# va416xx register map
Vendor: VORAGO TECHNOLOGIES; Series: M4; File version: 1.3
CPU: CM4 r0p1, little endian, no MPU, FPU, 4 interrupt priority bits
Registers are 32-bit, read-write, reset 0x0 unless marked. A register's access mark holds for its fields unless they carry their own. Offsets are from the block's base; [hi:lo] are bit positions; {n}, {i} and the like mark numbered series; 'fields as' and 'values as' point back to an identical list.

## SYSCONFIG — System Configuration Peripheral
Base 0x40010000
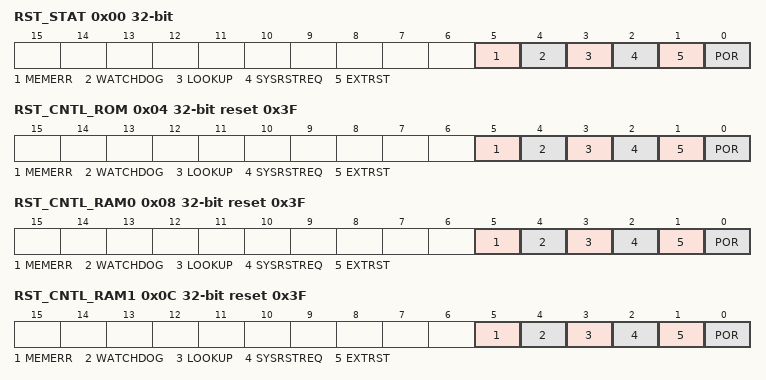
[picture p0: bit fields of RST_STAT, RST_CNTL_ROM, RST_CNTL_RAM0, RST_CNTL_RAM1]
0x00 RST_STAT — System Reset Status
  [5] MEMERR ro — Memory Error Reset Status
  [4] WATCHDOG — WATCHDOG Reset Status
  [3] LOOKUP — LOOKUP Reset Status
  [2] SYSRSTREQ — SYSRESETREQ Reset Status
  [1] EXTRST — External Reset Status
  [0] POR — Power On Reset Status
0x04 RST_CNTL_ROM reset 0x3F — ROM Reset Control
  fields as RST_STAT
0x08 RST_CNTL_RAM0 reset 0x3F — RAM Reset Control
  fields as RST_STAT
0x0C RST_CNTL_RAM1 reset 0x3F — RAM Reset Control
  fields as RST_STAT
0x10 ROM_PROT — ROM Protection Configuration
  [0] WREN — ROM Write Enable Bit
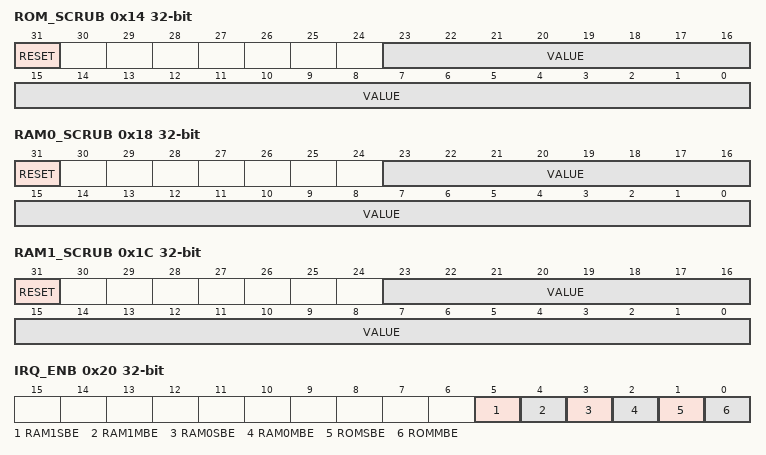
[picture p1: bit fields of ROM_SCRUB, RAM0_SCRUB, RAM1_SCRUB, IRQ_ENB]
0x14 ROM_SCRUB — ROM Scrub Period Configuration
  [31] RESET wo write-1-clears — Reset Counter
  [23:0] VALUE — Counter divide value
0x18 RAM0_SCRUB — RAM0 Scrub Period Configuration
  fields as ROM_SCRUB
0x1C RAM1_SCRUB — RAM1 Scrub Period Configuration
  fields as ROM_SCRUB
0x20 IRQ_ENB — Enable EDAC Error Interrupt Register
  [5] RAM1SBE — RAM1 Single Bit Interrupt
  [4] RAM1MBE — RAM1 Multi Bit Interrupt
  [3] RAM0SBE — RAM0 Single Bit Interrupt
  [2] RAM0MBE — RAM0 Multi Bit Interrupt
  [1] ROMSBE — ROM Single Bit Interrupt
  [0] ROMMBE — ROM Multi Bit Interrupt
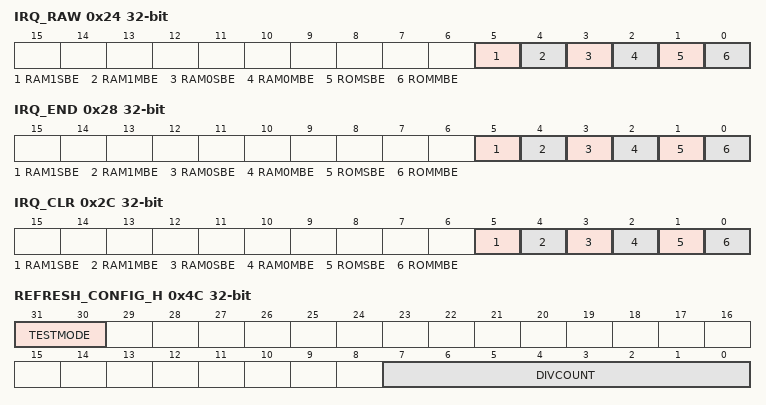
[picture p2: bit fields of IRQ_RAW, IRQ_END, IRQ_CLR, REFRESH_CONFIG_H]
0x24 IRQ_RAW ro — Raw EDAC Error Interrupt Status
  fields as IRQ_ENB
0x28 IRQ_END ro — Enabled EDAC Error Interrupt Status
  fields as IRQ_ENB
0x2C IRQ_CLR wo write-1-clears — Clear EDAC Error Interrupt Status
  fields as IRQ_ENB
0x30 RAM0_SBE — Count of RAM0 EDAC Single Bit Errors
  [15:0] COUNT — RAM0 EDAC Single Bit Errors
0x34 RAM1_SBE — Count of RAM1 EDAC Single Bit Errors
  [15:0] COUNT — RAM0 EDAC Single Bit Errors
0x38 RAM0_MBE — Count of RAM0 EDAC Multi Bit Errors
  [15:0] COUNT — RAM0 Multi Bit Errors
0x3C RAM1_MBE — Count of RAM1 EDAC Multi Bit Errors
  [15:0] COUNT — RAM0 Multi Bit Errors
0x40 ROM_SBE — Count of ROM EDAC Single Bit Errors
  [15:0] COUNT — RAM0 EDAC Single Bit Errors
0x44 ROM_MBE — Count of ROM EDAC Multi Bit Errors
  [15:0] COUNT — RAM0 Multi Bit Errors
0x48 ROM_RETRIES ro — ROM BOOT Retry count
  [7:0] COUNT — Count of ROM block Retries
0x4C REFRESH_CONFIG_H — Register Refresh Rate for TMR registers
  [31:30] TESTMODE — Special Test Mode Configuration. 00/01=normal. 10=Force refresh off. 11=Force refresh on constantly.
  [7:0] DIVCOUNT — Upper 8-bits of the Refresh Rate Counter. Registers are refreshed every DIVCOUNT+1 cycles
0x50 TIM_RESET reset 0xFFFFFFFF — TIM Reset Control
  [23:0] TIM_RESET — Reset of a given TIMER
0x54 TIM_CLK_ENABLE — TIM Enable Control
  [23:0] TIMERS — Clock enable of a given TIMER
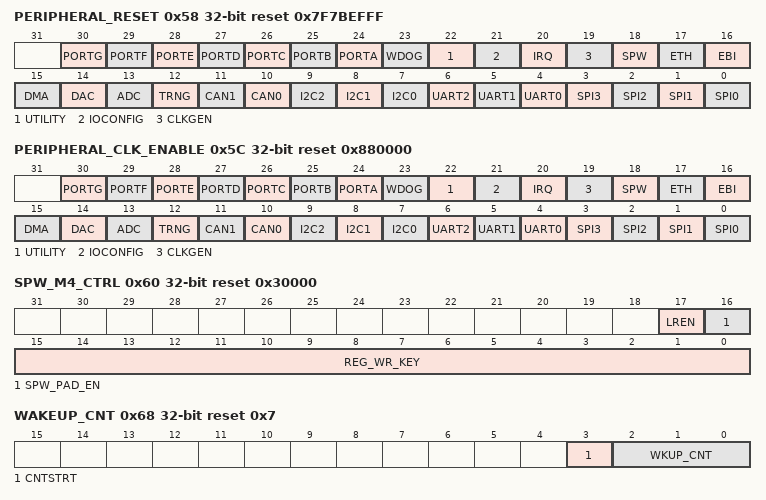
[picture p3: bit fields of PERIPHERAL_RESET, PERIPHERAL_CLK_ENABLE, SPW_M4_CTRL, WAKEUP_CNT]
0x58 PERIPHERAL_RESET reset 0x7F7BEFFF — Peripheral Reset Control
  [30] PORTG — Resetn of PORTG
  [29] PORTF — Resetn of PORTF
  [28] PORTE — Resetn of PORTE
  [27] PORTD — Resetn of PORTD
  [26] PORTC — Resetn of PORTC
  [25] PORTB — Resetn of PORTB
  [24] PORTA — Resetn of PORTA
  [23] WDOG — Resetn of WDOG
  [22] UTILITY — Resetn of UTILITY peripheral
  [21] IOCONFIG — Resetn of IO CONFIG
  [20] IRQ — Resetn of IRQ Router
  [19] CLKGEN — RESETn of PLL in Clock Generation Module
  [18] SPW — Resetn of SpaceWire
  [17] ETH — Resetn of Ethernet
  [16] EBI — Resetn of EBI
  [15] DMA — Resetn of DMA
  [14] DAC — Resetn of DAC
  [13] ADC — Resetn of ADC
  [12] TRNG — Resetn of TRNG
  [11] CAN1 — Resetn of CAN1
  [10] CAN0 — Resetn of CAN0
  [9] I2C2 — Resetn of I2C2
  [8] I2C1 — Resetn of I2C1
  [7] I2C0 — Resetn of I2C0
  [6] UART2 — Resetn of UART2
  [5] UART1 — Resetn of UART1
  [4] UART0 — Resetn of UART0
  [n] SPI{n} (n=0..3) — Resetn of SPI{n}
0x5C PERIPHERAL_CLK_ENABLE reset 0x880000 — Peripheral Enable Control
  fields as PERIPHERAL_RESET
0x60 SPW_M4_CTRL reset 0x30000 — SPW M4 control register
  [17] LREN — Lockup reset enable
  [16] SPW_PAD_EN — SPW pad enable
  [15:0] REG_WR_KEY — Fuse-analog register writes enabled when key = 0xfeed
0x64 PMU_CTRL — PMU Control Register
  [1:0] LVL_SLCT — Select the POK detect level
0x68 WAKEUP_CNT reset 0x7 — Wakeup Control
  [3] CNTSTRT — Launch SLP mode in analog block
  [2:0] WKUP_CNT — Used to set a time to wake up the processor after the device has been put in a low power state
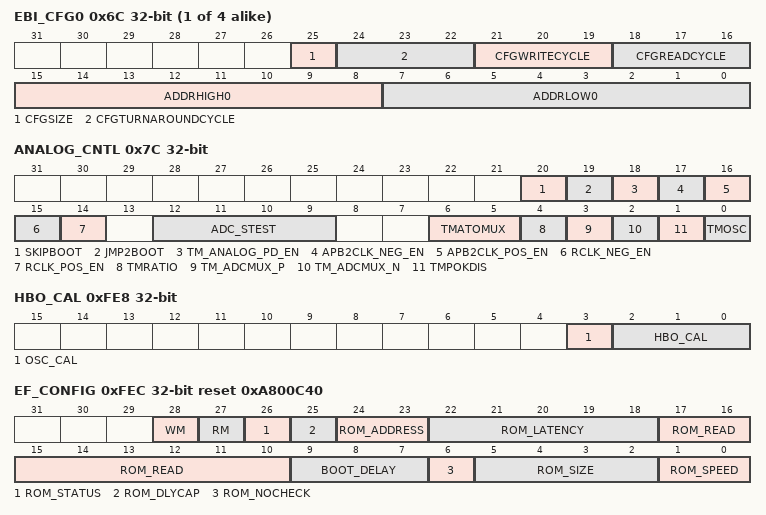
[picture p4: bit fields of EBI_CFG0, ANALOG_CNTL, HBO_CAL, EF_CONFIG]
{0x6C+4i} EBI_CFG{i} (i=0..3) — EBI Config Register {i}
  [25] CFGSIZE — 8 bit (0) or 16 bit (1) port size
  [24:22] CFGTURNAROUNDCYCLE — Number of cycles for turnaround - N plus 1
  [21:19] CFGWRITECYCLE — Number of cycles for a write - N plus 1
  [18:16] CFGREADCYCLE — Number of cycles for a read - N plus 1
  [15:8] ADDRHIGH0 — Upper bound address for CEN0
  [7:0] ADDRLOW0 — Lower bound address for CEN0
0x7C ANALOG_CNTL — Analog Control Register
  [20] SKIPBOOT — Enables a skip of all delay counters, eFuse read, and boot
  [19] JMP2BOOT — Enables a skip of all delay counters and eFuse read
  [18] TM_ANALOG_PD_EN — Enables pull down on analog pads
  [17] APB2CLK_NEG_EN — Enable inverted APB2CLK for test output
  [16] APB2CLK_POS_EN — Enable normal APB2CLK for test output
  [15] RCLK_NEG_EN — Enable inverted test clock
  [14] RCLK_POS_EN — Enable normal test clock
  [12:9] ADC_STEST — Number of clocks for sample time
  [6:5] TMATOMUX — Test Mode
  [4] TMRATIO — Test Mode
  [3] TM_ADCMUX_P — Test Mode
  [2] TM_ADCMUX_N — Test Mode
  [1] TMPOKDIS — Test Mode
  [0] TMOSC — Test Mode
0x80 SW_CLKDIV10 reset 0x9 — Initial SpW Clock Divider Value
  [7:0] SW_CLKDIV10 — Defines the initial value for the SpW clock, defaults to divide by ten
0x84 REFRESH_CONFIG_L reset 0xF — Register Refresh Rate for TMR registers
  [31:0] DIVCOUNT — Lower 32-bits of the Refresh Rate Counter. Registers are refreshed every DIVCOUNT+1 cycles
0xFD0 DAC0_CAL ro — DAC0 Calibration Register
  [4:0] DAC0_CAL — DAC0 Calibration bits
0xFD4 DAC1_CAL ro — DAC1 Calibration Register
  [4:0] DAC1_CAL — DAC1 Calibration bits
0xFD8 ADC_CAL ro — ADC Calibration Register
  [4:0] ADC_CAL — ADC Calibration bits
0xFDC BG_CAL ro — Bandgap Calibration Register
  [2:0] BG_CAL — Bandgap Calibration bits
0xFE0 DREG_CAL ro — Digital LDO Regulator Calibration Register
  [8:0] DREG_CAL — Digital LDO Regulator Calibration bits
0xFE4 AREG_CAL ro — Analog LDO Regulator Calibration Register
  [8:0] AREG_CAL — Analog LDO Regulator Calibration bits
0xFE8 HBO_CAL ro — Heart Beat OSC Calibration Register
  [3] OSC_CAL — 1MHz OSC Calibration bit
  [2:0] HBO_CAL — Heart Beat OSC Calibration bits
0xFEC EF_CONFIG ro reset 0xA800C40 — EFuse Config Register
  [28] WM — This bit controls the internal RAM write timing and must be maintained at this value
  [27] RM — This bit controls the internal RAM read timing and must be maintained at this value
  [26] ROM_STATUS — The first data byte from the SPI ROM following an address is taken as a status byte
  [25] ROM_DLYCAP — ROM SPI Delayed capture
  [24:23] ROM_ADDRESS — ROM Address Mode
  [22:18] ROM_LATENCY — Number of bits of latency from Address until data from the SPI ROM
  [17:10] ROM_READ — SPI ROM read instruction code
  [9:7] BOOT_DELAY — Specifies the boot delay from the end of the Power-On-Sequence to the release of Reset
  [6] ROM_NOCHECK — When set to 1, the ROM check is skipped
  [5:2] ROM_SIZE — Specifies how much of the full 128K byte address space is loaded from the external SPI memory after a reset
  [1:0] ROM_SPEED — Specifies the speed of ROM_SCK
0xFF0 EF_ID0 ro — EFuse ID0 Register
0xFF4 EF_ID1 ro — EFuse ID1 Register
0xFF8 PROCID ro reset 0x40057E3 — Processor ID Register
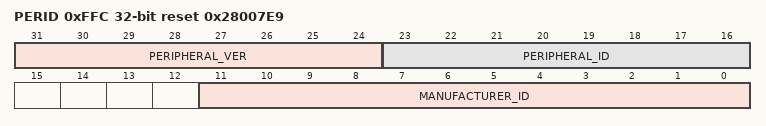
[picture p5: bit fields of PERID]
0xFFC PERID ro reset 0x28007E9 — Peripheral ID Register
  [31:24] PERIPHERAL_VER, [23:16] PERIPHERAL_ID, [11:0] MANUFACTURER_ID

## Notices in the file
Copyright (c) 2013-2020 VORAGO Technologies
BY DOWNLOADING, INSTALLING OR USING THIS SOFTWARE, YOU AGREE TO BE BOUND BY ALL THE TERMS
AND CONDITIONS OF THE VORAGO TECHNOLOGIES END USER LICENSE AGREEMENT.
THIS SOFTWARE IS PROVIDED "AS IS".  NO WARRANTIES, WHETHER EXPRESS, IMPLIED
OR STATUTORY, INCLUDING, BUT NOT LIMITED TO, IMPLIED WARRANTIES OF
MERCHANTABILITY AND FITNESS FOR A PARTICULAR PURPOSE APPLY TO THIS SOFTWARE.
VORAGO TECHNOLOGIES SHALL NOT, IN ANY CIRCUMSTANCES, BE LIABLE
FOR SPECIAL, INCIDENTAL, OR CONSEQUENTIAL DAMAGES, FOR ANY REASON WHATSOEVER.
